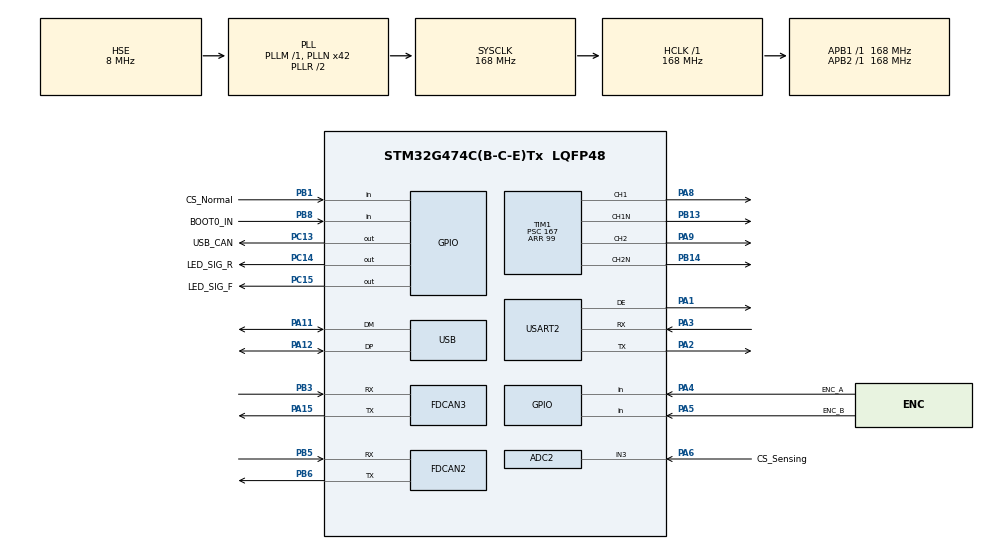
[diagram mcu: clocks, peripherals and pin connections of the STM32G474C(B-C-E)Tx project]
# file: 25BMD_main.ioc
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ADC2.Channel-0\#ChannelRegularConversion=ADC_CHANNEL_3
ADC2.NbrOfConversionFlag=1
ADC2.OffsetNumber-0\#ChannelRegularConversion=ADC_OFFSET_NONE
ADC2.Rank-0\#ChannelRegularConversion=1
ADC2.SamplingTime-0\#ChannelRegularConversion=ADC_SAMPLETIME_2CYCLES_5
FDCAN2.CalculateBaudRateNominal=2100000
FDCAN2.CalculateTimeBitNominal=476
FDCAN2.CalculateTimeQuantumNominal=95.23809523809524
FDCAN3.CalculateBaudRateNominal=2100000
FDCAN3.CalculateTimeBitNominal=476
FDCAN3.CalculateTimeQuantumNominal=95.23809523809524
Mcu.Family=STM32G4
Mcu.Name=STM32G474C(B-C-E)Tx
Mcu.Package=LQFP48
NVIC.PriorityGroup=NVIC_PRIORITYGROUP_4
PA1.Mode=Hardware Flow Control (RS485)
PA1.Signal=USART2_DE
PA11.Mode=Device
PA11.Signal=USB_DM
PA12.Mode=Device
PA12.Signal=USB_DP
PA15.Mode=FDCAN_Activate
PA15.Signal=FDCAN3_TX
PA2.Mode=Asynchronous
PA2.Signal=USART2_TX
PA3.Mode=Asynchronous
PA3.Signal=USART2_RX
PA4.GPIO_Label=ENC_A
PA4.Signal=GPIO_Input
PA5.GPIO_Label=ENC_B
PA5.Signal=GPIO_Input
PA6.GPIO_Label=CS_Sensing
PA6.Mode=IN3-Single-Ended
PA6.Signal=ADC2_IN3
PA8.Signal=S_TIM1_CH1
PA9.Signal=S_TIM1_CH2
PB1.GPIO_Label=CS_Normal
PB1.Signal=GPIO_Input
PB13.Mode=PWM Generation1 CH1 CH1N
PB13.Signal=TIM1_CH1N
PB14.Mode=PWM Generation2 CH2 CH2N
PB14.Signal=TIM1_CH2N
PB3.Mode=FDCAN_Activate
PB3.Signal=FDCAN3_RX
PB5.Mode=FDCAN_Activate
PB5.Signal=FDCAN2_RX
PB6.Mode=FDCAN_Activate
PB6.Signal=FDCAN2_TX
PB8-BOOT0.GPIO_Label=BOOT0_IN
PB8-BOOT0.Signal=GPIO_Input
PC13.GPIO_Label=USB_CAN
PC13.Signal=GPIO_Output
PC14-OSC32_IN.GPIO_Label=LED_SIG_R
PC14-OSC32_IN.Signal=GPIO_Output
PC15-OSC32_OUT.GPIO_Label=LED_SIG_F
PC15-OSC32_OUT.Signal=GPIO_Output
PF0-OSC_IN.Mode=HSE-External-Oscillator
PF0-OSC_IN.Signal=RCC_OSC_IN
PF1-OSC_OUT.Mode=HSE-External-Oscillator
PF1-OSC_OUT.Signal=RCC_OSC_OUT
ProjectManager.HeapSize=0x200
ProjectManager.StackSize=0x400
ProjectManager.TargetToolchain=STM32CubeIDE
RCC.ADC12Freq_Value=168000000
RCC.ADC345Freq_Value=168000000
RCC.AHBFreq_Value=168000000
RCC.APB1Freq_Value=168000000
RCC.APB1TimFreq_Value=168000000
RCC.APB2Freq_Value=168000000
RCC.APB2TimFreq_Value=168000000
RCC.CK48CLockSelection=RCC_USBCLKSOURCE_HSI48
RCC.CortexFreq_Value=168000000
RCC.EXTERNAL_CLOCK_VALUE=12288000
RCC.HCLKFreq_Value=168000000
RCC.HSE_VALUE=8000000
RCC.HSI48_VALUE=48000000
RCC.HSI_VALUE=16000000
RCC.LSE_VALUE=32768
RCC.PLLN=42
RCC.PLLSourceVirtual=RCC_PLLSOURCE_HSE
RCC.SYSCLKFreq_VALUE=168000000
RCC.SYSCLKSource=RCC_SYSCLKSOURCE_PLLCLK
RCC.USBFreq_Value=48000000
RCC.VCOOutputFreq_Value=336000000
SH.S_TIM1_CH1.0=TIM1_CH1,PWM Generation1 CH1 CH1N
SH.S_TIM1_CH2.0=TIM1_CH2,PWM Generation2 CH2 CH2N
TIM1.Channel-PWM\ Generation1\ CH1\ CH1N=TIM_CHANNEL_1
TIM1.Channel-PWM\ Generation2\ CH2\ CH2N=TIM_CHANNEL_2
TIM1.PeriodNoDither=99
TIM1.Prescaler=167
USART2.VirtualMode-Asynchronous=VM_ASYNC
USART2.VirtualMode-Hardware\ Flow\ Control\ (RS485)=VM_ASYNC
VP_SYS_VS_DBSignals.Mode=DisableDeadBatterySignals
VP_TIM1_VS_ClockSourceINT.Mode=Internal
board=custom

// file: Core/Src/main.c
/* USER CODE BEGIN Header */
/* USER CODE END Header */
#include "main.h"

ADC_HandleTypeDef hadc2;

FDCAN_HandleTypeDef hfdcan2;
FDCAN_HandleTypeDef hfdcan3;

TIM_HandleTypeDef htim1;

UART_HandleTypeDef huart2;

PCD_HandleTypeDef hpcd_USB_FS;

void SystemClock_Config(void);
static void MX_GPIO_Init(void);
static void MX_ADC2_Init(void);
static void MX_FDCAN2_Init(void);
static void MX_FDCAN3_Init(void);
static void MX_TIM1_Init(void);
static void MX_USART2_UART_Init(void);
static void MX_USB_PCD_Init(void);

int main(void)
{

  /* MCU Configuration--------------------------------------------------------*/

  /* Reset of all peripherals, Initializes the Flash interface and the Systick. */
  HAL_Init();

  /* Configure the system clock */
  SystemClock_Config();

  /* Initialize all configured peripherals */
  MX_GPIO_Init();
  MX_ADC2_Init();
  MX_FDCAN2_Init();
  MX_FDCAN3_Init();
  MX_TIM1_Init();
  MX_USART2_UART_Init();
  MX_USB_PCD_Init();
  HAL_TIM_PWM_Start(&htim1, TIM_CHANNEL_1);
  HAL_TIMEx_PWMN_Start(&htim1, TIM_CHANNEL_1);

  int Duty = 5000;
  /* Infinite loop */
  while(1){
  /* USER CODE BEGIN WHILE */
	  while(Duty < 100){
		  Duty += 10;
		  __HAL_TIM_SET_COMPARE(&htim1, TIM_CHANNEL_1, Duty);
		  HAL_Delay(100);
	  }
	  Duty = 0;
    /* USER CODE END WHILE */
  }
}

void SystemClock_Config(void)
{
  RCC_OscInitTypeDef RCC_OscInitStruct = {0};
  RCC_ClkInitTypeDef RCC_ClkInitStruct = {0};

  /** Configure the main internal regulator output voltage
  */
  HAL_PWREx_ControlVoltageScaling(PWR_REGULATOR_VOLTAGE_SCALE1_BOOST);

  /** Initializes the RCC Oscillators according to the specified parameters
  * in the RCC_OscInitTypeDef structure.
  */
  RCC_OscInitStruct.OscillatorType = RCC_OSCILLATORTYPE_HSI48|RCC_OSCILLATORTYPE_HSE;
  RCC_OscInitStruct.HSEState = RCC_HSE_ON;
  RCC_OscInitStruct.HSI48State = RCC_HSI48_ON;
  RCC_OscInitStruct.PLL.PLLState = RCC_PLL_ON;
  RCC_OscInitStruct.PLL.PLLSource = RCC_PLLSOURCE_HSE;
  RCC_OscInitStruct.PLL.PLLM = RCC_PLLM_DIV1;
  RCC_OscInitStruct.PLL.PLLN = 42;
  RCC_OscInitStruct.PLL.PLLP = RCC_PLLP_DIV2;
  RCC_OscInitStruct.PLL.PLLQ = RCC_PLLQ_DIV2;
  RCC_OscInitStruct.PLL.PLLR = RCC_PLLR_DIV2;
  if (HAL_RCC_OscConfig(&RCC_OscInitStruct) != HAL_OK)
  {
    Error_Handler();
  }

  /** Initializes the CPU, AHB and APB buses clocks
  */
  RCC_ClkInitStruct.ClockType = RCC_CLOCKTYPE_HCLK|RCC_CLOCKTYPE_SYSCLK
                              |RCC_CLOCKTYPE_PCLK1|RCC_CLOCKTYPE_PCLK2;
  RCC_ClkInitStruct.SYSCLKSource = RCC_SYSCLKSOURCE_PLLCLK;
  RCC_ClkInitStruct.AHBCLKDivider = RCC_SYSCLK_DIV1;
  RCC_ClkInitStruct.APB1CLKDivider = RCC_HCLK_DIV1;
  RCC_ClkInitStruct.APB2CLKDivider = RCC_HCLK_DIV1;

  if (HAL_RCC_ClockConfig(&RCC_ClkInitStruct, FLASH_LATENCY_4) != HAL_OK)
  {
    Error_Handler();
  }
}

static void MX_ADC2_Init(void)
{

  ADC_ChannelConfTypeDef sConfig = {0};

  /** Common config
  */
  hadc2.Instance = ADC2;
  hadc2.Init.ClockPrescaler = ADC_CLOCK_SYNC_PCLK_DIV4;
  hadc2.Init.Resolution = ADC_RESOLUTION_12B;
  hadc2.Init.DataAlign = ADC_DATAALIGN_RIGHT;
  hadc2.Init.GainCompensation = 0;
  hadc2.Init.ScanConvMode = ADC_SCAN_DISABLE;
  hadc2.Init.EOCSelection = ADC_EOC_SINGLE_CONV;
  hadc2.Init.LowPowerAutoWait = DISABLE;
  hadc2.Init.ContinuousConvMode = DISABLE;
  hadc2.Init.NbrOfConversion = 1;
  hadc2.Init.DiscontinuousConvMode = DISABLE;
  hadc2.Init.ExternalTrigConv = ADC_SOFTWARE_START;
  hadc2.Init.ExternalTrigConvEdge = ADC_EXTERNALTRIGCONVEDGE_NONE;
  hadc2.Init.DMAContinuousRequests = DISABLE;
  hadc2.Init.Overrun = ADC_OVR_DATA_PRESERVED;
  hadc2.Init.OversamplingMode = DISABLE;
  if (HAL_ADC_Init(&hadc2) != HAL_OK)
  {
    Error_Handler();
  }

  /** Configure Regular Channel
  */
  sConfig.Channel = ADC_CHANNEL_3;
  sConfig.Rank = ADC_REGULAR_RANK_1;
  sConfig.SamplingTime = ADC_SAMPLETIME_2CYCLES_5;
  sConfig.SingleDiff = ADC_SINGLE_ENDED;
  sConfig.OffsetNumber = ADC_OFFSET_NONE;
  sConfig.Offset = 0;
  if (HAL_ADC_ConfigChannel(&hadc2, &sConfig) != HAL_OK)
  {
    Error_Handler();
  }

}

static void MX_FDCAN2_Init(void)
{

  hfdcan2.Instance = FDCAN2;
  hfdcan2.Init.ClockDivider = FDCAN_CLOCK_DIV1;
  hfdcan2.Init.FrameFormat = FDCAN_FRAME_CLASSIC;
  hfdcan2.Init.Mode = FDCAN_MODE_NORMAL;
  hfdcan2.Init.AutoRetransmission = DISABLE;
  hfdcan2.Init.TransmitPause = DISABLE;
  hfdcan2.Init.ProtocolException = DISABLE;
  hfdcan2.Init.NominalPrescaler = 16;
  hfdcan2.Init.NominalSyncJumpWidth = 1;
  hfdcan2.Init.NominalTimeSeg1 = 2;
  hfdcan2.Init.NominalTimeSeg2 = 2;
  hfdcan2.Init.DataPrescaler = 1;
  hfdcan2.Init.DataSyncJumpWidth = 1;
  hfdcan2.Init.DataTimeSeg1 = 1;
  hfdcan2.Init.DataTimeSeg2 = 1;
  hfdcan2.Init.StdFiltersNbr = 0;
  hfdcan2.Init.ExtFiltersNbr = 0;
  hfdcan2.Init.TxFifoQueueMode = FDCAN_TX_FIFO_OPERATION;
  if (HAL_FDCAN_Init(&hfdcan2) != HAL_OK)
  {
    Error_Handler();
  }

}

static void MX_FDCAN3_Init(void)
{

  hfdcan3.Instance = FDCAN3;
  hfdcan3.Init.ClockDivider = FDCAN_CLOCK_DIV1;
  hfdcan3.Init.FrameFormat = FDCAN_FRAME_CLASSIC;
  hfdcan3.Init.Mode = FDCAN_MODE_NORMAL;
  hfdcan3.Init.AutoRetransmission = DISABLE;
  hfdcan3.Init.TransmitPause = DISABLE;
  hfdcan3.Init.ProtocolException = DISABLE;
  hfdcan3.Init.NominalPrescaler = 16;
  hfdcan3.Init.NominalSyncJumpWidth = 1;
  hfdcan3.Init.NominalTimeSeg1 = 2;
  hfdcan3.Init.NominalTimeSeg2 = 2;
  hfdcan3.Init.DataPrescaler = 1;
  hfdcan3.Init.DataSyncJumpWidth = 1;
  hfdcan3.Init.DataTimeSeg1 = 1;
  hfdcan3.Init.DataTimeSeg2 = 1;
  hfdcan3.Init.StdFiltersNbr = 0;
  hfdcan3.Init.ExtFiltersNbr = 0;
  hfdcan3.Init.TxFifoQueueMode = FDCAN_TX_FIFO_OPERATION;
  if (HAL_FDCAN_Init(&hfdcan3) != HAL_OK)
  {
    Error_Handler();
  }

}

static void MX_TIM1_Init(void)
{

  TIM_ClockConfigTypeDef sClockSourceConfig = {0};
  TIM_MasterConfigTypeDef sMasterConfig = {0};
  TIM_OC_InitTypeDef sConfigOC = {0};
  TIM_BreakDeadTimeConfigTypeDef sBreakDeadTimeConfig = {0};

  htim1.Instance = TIM1;
  htim1.Init.Prescaler = 167;
  htim1.Init.CounterMode = TIM_COUNTERMODE_UP;
  htim1.Init.Period = 99;
  htim1.Init.ClockDivision = TIM_CLOCKDIVISION_DIV1;
  htim1.Init.RepetitionCounter = 0;
  htim1.Init.AutoReloadPreload = TIM_AUTORELOAD_PRELOAD_DISABLE;
  if (HAL_TIM_Base_Init(&htim1) != HAL_OK)
  {
    Error_Handler();
  }
  sClockSourceConfig.ClockSource = TIM_CLOCKSOURCE_INTERNAL;
  if (HAL_TIM_ConfigClockSource(&htim1, &sClockSourceConfig) != HAL_OK)
  {
    Error_Handler();
  }
  if (HAL_TIM_PWM_Init(&htim1) != HAL_OK)
  {
    Error_Handler();
  }
  sMasterConfig.MasterOutputTrigger = TIM_TRGO_RESET;
  sMasterConfig.MasterOutputTrigger2 = TIM_TRGO2_RESET;
  sMasterConfig.MasterSlaveMode = TIM_MASTERSLAVEMODE_DISABLE;
  if (HAL_TIMEx_MasterConfigSynchronization(&htim1, &sMasterConfig) != HAL_OK)
  {
    Error_Handler();
  }
  sConfigOC.OCMode = TIM_OCMODE_PWM1;
  sConfigOC.Pulse = 0;
  sConfigOC.OCPolarity = TIM_OCPOLARITY_HIGH;
  sConfigOC.OCNPolarity = TIM_OCNPOLARITY_HIGH;
  sConfigOC.OCFastMode = TIM_OCFAST_DISABLE;
  sConfigOC.OCIdleState = TIM_OCIDLESTATE_RESET;
  sConfigOC.OCNIdleState = TIM_OCNIDLESTATE_RESET;
  if (HAL_TIM_PWM_ConfigChannel(&htim1, &sConfigOC, TIM_CHANNEL_1) != HAL_OK)
  {
    Error_Handler();
  }
  if (HAL_TIM_PWM_ConfigChannel(&htim1, &sConfigOC, TIM_CHANNEL_2) != HAL_OK)
  {
    Error_Handler();
  }
  sBreakDeadTimeConfig.OffStateRunMode = TIM_OSSR_DISABLE;
  sBreakDeadTimeConfig.OffStateIDLEMode = TIM_OSSI_DISABLE;
  sBreakDeadTimeConfig.LockLevel = TIM_LOCKLEVEL_OFF;
  sBreakDeadTimeConfig.DeadTime = 0;
  sBreakDeadTimeConfig.BreakState = TIM_BREAK_DISABLE;
  sBreakDeadTimeConfig.BreakPolarity = TIM_BREAKPOLARITY_HIGH;
  sBreakDeadTimeConfig.BreakFilter = 0;
  sBreakDeadTimeConfig.BreakAFMode = TIM_BREAK_AFMODE_INPUT;
  sBreakDeadTimeConfig.Break2State = TIM_BREAK2_DISABLE;
  sBreakDeadTimeConfig.Break2Polarity = TIM_BREAK2POLARITY_HIGH;
  sBreakDeadTimeConfig.Break2Filter = 0;
  sBreakDeadTimeConfig.Break2AFMode = TIM_BREAK_AFMODE_INPUT;
  sBreakDeadTimeConfig.AutomaticOutput = TIM_AUTOMATICOUTPUT_DISABLE;
  if (HAL_TIMEx_ConfigBreakDeadTime(&htim1, &sBreakDeadTimeConfig) != HAL_OK)
  {
    Error_Handler();
  }
  HAL_TIM_MspPostInit(&htim1);

}

static void MX_USART2_UART_Init(void)
{

  huart2.Instance = USART2;
  huart2.Init.BaudRate = 115200;
  huart2.Init.WordLength = UART_WORDLENGTH_8B;
  huart2.Init.StopBits = UART_STOPBITS_1;
  huart2.Init.Parity = UART_PARITY_NONE;
  huart2.Init.Mode = UART_MODE_TX_RX;
  huart2.Init.HwFlowCtl = UART_HWCONTROL_NONE;
  huart2.Init.OverSampling = UART_OVERSAMPLING_16;
  huart2.Init.OneBitSampling = UART_ONE_BIT_SAMPLE_DISABLE;
  huart2.Init.ClockPrescaler = UART_PRESCALER_DIV1;
  huart2.AdvancedInit.AdvFeatureInit = UART_ADVFEATURE_NO_INIT;
  if (HAL_RS485Ex_Init(&huart2, UART_DE_POLARITY_HIGH, 0, 0) != HAL_OK)
  {
    Error_Handler();
  }
  if (HAL_UARTEx_SetTxFifoThreshold(&huart2, UART_TXFIFO_THRESHOLD_1_8) != HAL_OK)
  {
    Error_Handler();
  }
  if (HAL_UARTEx_SetRxFifoThreshold(&huart2, UART_RXFIFO_THRESHOLD_1_8) != HAL_OK)
  {
    Error_Handler();
  }
  if (HAL_UARTEx_DisableFifoMode(&huart2) != HAL_OK)
  {
    Error_Handler();
  }

}

static void MX_USB_PCD_Init(void)
{

  hpcd_USB_FS.Instance = USB;
  hpcd_USB_FS.Init.dev_endpoints = 8;
  hpcd_USB_FS.Init.speed = PCD_SPEED_FULL;
  hpcd_USB_FS.Init.phy_itface = PCD_PHY_EMBEDDED;
  hpcd_USB_FS.Init.Sof_enable = DISABLE;
  hpcd_USB_FS.Init.low_power_enable = DISABLE;
  hpcd_USB_FS.Init.lpm_enable = DISABLE;
  hpcd_USB_FS.Init.battery_charging_enable = DISABLE;
  if (HAL_PCD_Init(&hpcd_USB_FS) != HAL_OK)
  {
    Error_Handler();
  }

}

static void MX_GPIO_Init(void)
{
  GPIO_InitTypeDef GPIO_InitStruct = {0};

  /* GPIO Ports Clock Enable */
  __HAL_RCC_GPIOC_CLK_ENABLE();
  __HAL_RCC_GPIOF_CLK_ENABLE();
  __HAL_RCC_GPIOA_CLK_ENABLE();
  __HAL_RCC_GPIOB_CLK_ENABLE();

  /*Configure GPIO pin Output Level */
  HAL_GPIO_WritePin(GPIOC, USB_CAN_Pin|LED_SIG_R_Pin|LED_SIG_F_Pin, GPIO_PIN_RESET);

  /*Configure GPIO pins : USB_CAN_Pin LED_SIG_R_Pin LED_SIG_F_Pin */
  GPIO_InitStruct.Pin = USB_CAN_Pin|LED_SIG_R_Pin|LED_SIG_F_Pin;
  GPIO_InitStruct.Mode = GPIO_MODE_OUTPUT_PP;
  GPIO_InitStruct.Pull = GPIO_NOPULL;
  GPIO_InitStruct.Speed = GPIO_SPEED_FREQ_LOW;
  HAL_GPIO_Init(GPIOC, &GPIO_InitStruct);

  /*Configure GPIO pins : ENC_A_Pin ENC_B_Pin */
  GPIO_InitStruct.Pin = ENC_A_Pin|ENC_B_Pin;
  GPIO_InitStruct.Mode = GPIO_MODE_INPUT;
  GPIO_InitStruct.Pull = GPIO_NOPULL;
  HAL_GPIO_Init(GPIOA, &GPIO_InitStruct);

  /*Configure GPIO pins : CS_Normal_Pin BOOT0_IN_Pin */
  GPIO_InitStruct.Pin = CS_Normal_Pin|BOOT0_IN_Pin;
  GPIO_InitStruct.Mode = GPIO_MODE_INPUT;
  GPIO_InitStruct.Pull = GPIO_NOPULL;
  HAL_GPIO_Init(GPIOB, &GPIO_InitStruct);

}

void Error_Handler(void)
{
}
